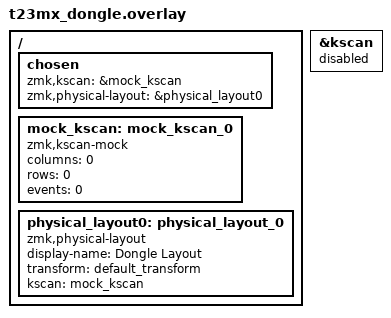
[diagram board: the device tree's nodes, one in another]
// Dongle (central) build: no local key scanning, just act as BLE central + USB.

#include "t23mx.dtsi"

/ {
    chosen {
        // Use a mock kscan since the dongle has no keys.
        zmk,kscan = &mock_kscan;
        zmk,physical-layout = &physical_layout0;
    };

    mock_kscan: mock_kscan_0 {
        compatible = "zmk,kscan-mock";
        columns = <0>;
        rows = <0>;
        events = <0>;
    };

    physical_layout0: physical_layout_0 {
        compatible = "zmk,physical-layout";
        display-name = "Dongle Layout";
        transform = <&default_transform>;
        kscan = <&mock_kscan>;
    };
};

&kscan {
    status = "disabled";
};
